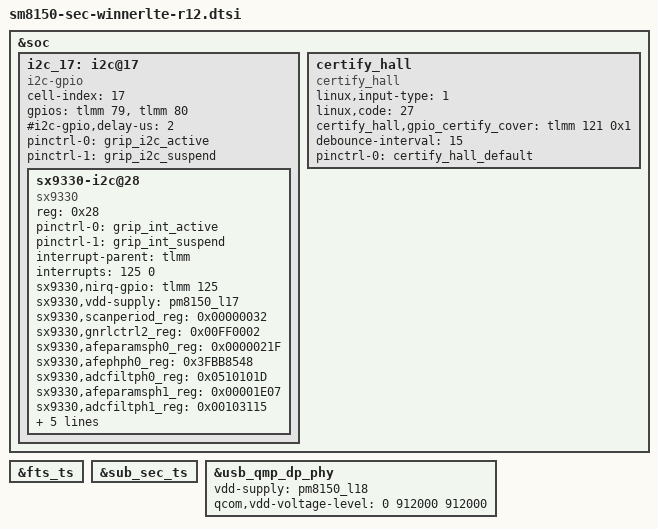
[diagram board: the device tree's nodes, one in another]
/* Copyright (c) 2016-2017, The Linux Foundation. All rights reserved.
 *
 * This program is free software; you can redistribute it and/or modify
 * it under the terms of the GNU General Public License version 2 and
 * only version 2 as published by the Free Software Foundation.
 *
 * This program is distributed in the hope that it will be useful,
 * but WITHOUT ANY WARRANTY; without even the implied warranty of
 * MERCHANTABILITY or FITNESS FOR A PARTICULAR PURPOSE.  See the
 * GNU General Public License for more details.
 */

#include "sm8150-sec-winnerlte-common.dtsi"
#include "sm8150-sec-winnerlte-optics-r00.dtsi"

&soc {
	i2c_17: i2c@17 { /* SW I2C */
		status = "ok";

		cell-index = <17>;
		compatible = "i2c-gpio";
		gpios = <&tlmm 79 0 /* sda */
			 &tlmm 80 0 /* scl */
		>;
		#i2c-gpio,delay-us = <2>;
		#address-cells = <1>;
		#size-cells = <0>;

		pinctrl-names = "default", "sleep";
		pinctrl-0 = <&grip_i2c_active>;
		pinctrl-1 = <&grip_i2c_suspend>;

		sx9330-i2c@28 {
			compatible = "sx9330";
			reg = <0x28>;

			pinctrl-names = "default", "sleep";
			pinctrl-0 = <&grip_int_active>;
			pinctrl-1 = <&grip_int_suspend>;

			interrupt-parent = <&tlmm>;
			interrupts = <125 0>;

			sx9330,nirq-gpio = <&tlmm 125 0>;
			sx9330,vdd-supply = <&pm8150_l17>;

			sx9330,scanperiod_reg = <0x00000032>; /* scanperiod : 102ms */
			sx9330,gnrlctrl2_reg = <0x00FF0002>;
			sx9330,afeparamsph0_reg = <0x0000021F>;
			sx9330,afephph0_reg = <0x3FBB8548>;
			sx9330,adcfiltph0_reg = <0x0510101D>;
			sx9330,afeparamsph1_reg = <0x00001E07>;  /* again : 9.9pF, sampling freq : 250khz */
			sx9330,adcfiltph1_reg = <0x00103115>;    /* threshold : 1275 */
			sx9330,avgbfilt_reg = <0x60600C00>;   /* AVGPOSFILT : 1/256, AVGNEGFILT : 1/2 */
			sx9330,avgafilt_reg = <0x00000000>;
			sx9330,advdig3_reg = <0x00000000>;
			sx9330,advdig4_reg = <0x00000000>;
			sx9330,refcorra_reg = <0x00000000>;
		};
	};

        certify_hall {
                compatible = "certify_hall";
                linux,input-type = <1>;
                linux,code = <27>;
                certify_hall,gpio_certify_cover = <&tlmm 121 0x1>;
                debounce-interval = <15>;
		pinctrl-names = "default";
	        pinctrl-0 = <&certify_hall_default>;
        };

};

&fts_ts { /* main_tsp */
	status = "ok";
};

&sub_sec_ts { /* sub_tsp */
	status = "ok";
};

&usb_qmp_dp_phy {
	vdd-supply = <&pm8150_l18>;
	qcom,vdd-voltage-level = <0 912000 912000>;
};
